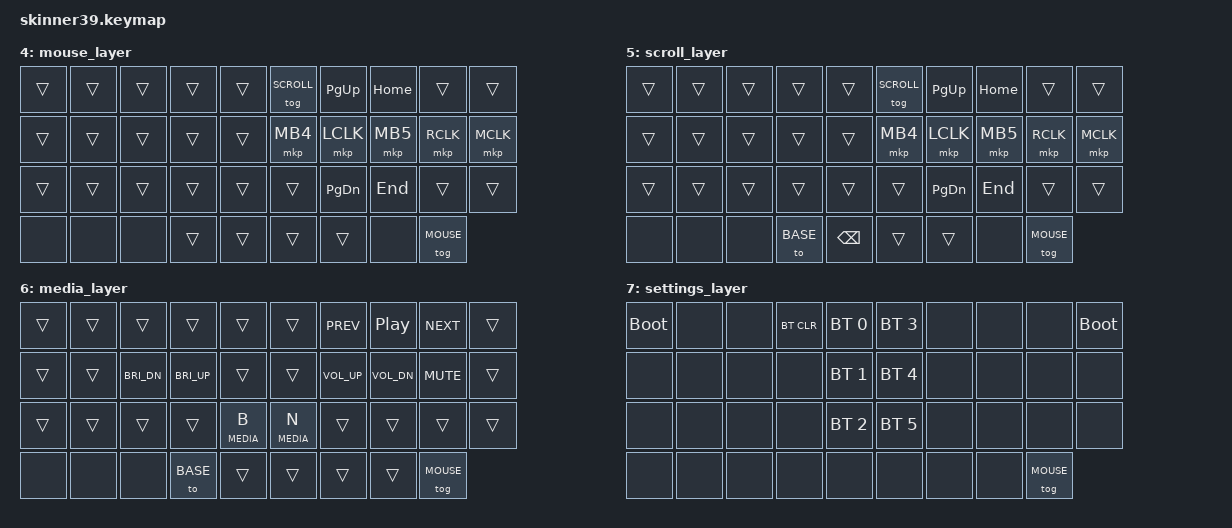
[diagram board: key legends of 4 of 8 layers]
#include <behaviors.dtsi>
#include <dt-bindings/zmk/bt.h>
#include <dt-bindings/zmk/keys.h>
#include <dt-bindings/zmk/mouse.h>
#include <dt-bindings/zmk/pointing.h>
#include <zephyr/dt-bindings/input/input-event-codes.h>

// Home row mods macro
#define HRML(k1,k2,k3,k4) &ht LSHFT k1  &ht LALT k2  &ht LCTRL k3  &ht LGUI k4
#define HRMR(k1,k2,k3,k4) &ht RGUI k1  &ht RCTRL k2  &ht RALT k3  &ht RSHFT k4
#define HYPERHT(k1) &ht LC(LS(LA(LGUI))) k1

// Layer definitions
#define BASE 0
#define NAV 1
#define NUM 2
#define SYMBOL 3
#define MOUSE 4
#define SCROLL 5
#define MEDIA 6
#define SETTINGS 7

&mmv {
    time-to-max-speed-ms = <500>;
};

/ {
    input_processors {
        // Maps Y movement to high-resolution vertical scroll
        zip_y_to_vscroll_mapper: zip_y_to_vscroll_mapper {
            compatible = "zmk,input-processor-code-mapper";
            #input-processor-cells = <0>;
            type = <INPUT_EV_REL>;
            map = <INPUT_REL_Y INPUT_REL_WHEEL>;  // Y only -> vertical scroll
        };
        
        // Inverts Y direction (scaler with -1 multiplier)
        zip_y_scaler_neg1_1: zip_y_scaler_neg1_1 {
            compatible = "zmk,input-processor-scaler";
            #input-processor-cells = <2>;  // Takes multiplier and divisor as params
            type = <INPUT_EV_REL>;
            codes = <INPUT_REL_Y>;
        };
        
        // Slows down scrolling (1/2 speed = 50%)
        zip_scroll_slow: zip_scroll_slow {
            compatible = "zmk,input-processor-scaler";
            #input-processor-cells = <2>;
            type = <INPUT_EV_REL>;
            codes = <INPUT_REL_Y>;
        };
        
    };

    macros {
        vol_up: vol_up {
            compatible = "zmk,behavior-macro";
            #binding-cells = <0>;
            bindings = <&kp C_VOL_UP>;
        };
        vol_down: vol_down {
            compatible = "zmk,behavior-macro";
            #binding-cells = <0>;
            bindings = <&kp C_VOL_DN>;
        };
    };

    behaviors {
        ht: hold_tap {
            compatible = "zmk,behavior-hold-tap";
            #binding-cells = <2>;
            flavor = "tap-preferred";
            tapping-term-ms = <220>;
            quick-tap-ms = <150>;
            bindings = <&kp>, <&kp>;
        };
    };

    combos {
        compatible = "zmk,combos";
        combo_caps_word {
            timeout-ms = <150>;
            key-positions = <20 29>;
            bindings = <&caps_word>;
        };
        combo_minus {
            timeout-ms = <150>;
            key-positions = <3 6>;
            bindings = <&kp MINUS>;
        };
        combo_under {
            timeout-ms = <150>;
            key-positions = <23 26>;
            bindings = <&kp UNDER>;
        };
    };

    keymap {
        compatible = "zmk,keymap";

        base_layer {
            bindings = <
        // Row 0: Main 5x3 grid (positions 0-4 left, 5-9 right)
        //╭──────────┬──────────┬──────────┬──────────┬──────────╮   ╭──────────┬──────────┬──────────┬──────────┬──────────╮
        //│  Q       │  W       │  E       │  R       │  T       │   │  Y       │  U       │  I       │  O       │  P       │
            &kp Q      &kp W      &kp E      &kp R      &kp T          &kp Y      &kp U      &kp I      &kp O      &kp P
        //├──────────┼──────────┼──────────┼──────────┼──────────┤   ├──────────┼──────────┼──────────┼──────────┼──────────┤
        // Row 1: Main 5x3 grid (positions 10-14 left, 15-19 right)
        //│  A       │  S       │  D       │  F       │  G       │   │  H       │  J       │  K       │  L       │    ' "   │
            HRML(A,        S,         D,         F)     &kp G          &kp H      HRMR(J,        K,         L,     APOSTROPHE)
        //├──────────┼──────────┼──────────┼──────────┼──────────┤   ├──────────┼──────────┼──────────┼──────────┼──────────┤
        // Row 2: Main 5x3 grid (positions 20-24 left, 25-29 right)
        //│  Z       │  X       │  C       │  V       │  B       │   │  N       │  M       │ , <      │ . >      │ / ?      │
            &kp Z      &kp X      &kp C      &kp V   &lt MEDIA B   &lt MEDIA N  &kp M   &kp COMMA  &kp DOT    &kp FSLH
        //╰──────────┴──────────┴──────────┴──────────┴──────────╯   ╰──────────┴──────────┴──────────┴──────────┴──────────╯

        // Row 3: Extra keys + Thumb keys (positions 30-38)
        // Layout: | Left Extra (3) | Left Thumbs (3) | Right Thumbs (2) | Right Extra (1) |
        // Matrix:   RC30 RC31 RC32   RC33 RC34 RC35   RC36 RC37          RC38
        //╭──────────┬──────────┬──────────┬──────────┬──────────┬──────────╮   ╭──────────┬──────────┬──────────╮
        //│ SCROLL   │  none    │  none    │  MOUSE   │ NUM/TAB  │HYPER/BSP │   │  SPACE   │  SPACE   │MOUSE TOG │
            &mo SCROLL &none      &none      &mo MOUSE  &lt NUM TAB    HYPERHT(BSPC)  &lt SYMBOL SPACE &lt NAV SPACE &tog MOUSE
        //╰──────────┴──────────┴──────────┴──────────┴──────────┴──────────╯   ╰──────────┴──────────┴──────────╯
            >;
        };

        nav_layer {
            bindings = <
        // Row 0
            &none &kp RG(W) &kp RG(LEFT_BRACKET) &kp RG(RIGHT_BRACKET) &kp RG(T)     &kp DEL &kp HOME &kp UP   &kp END  &kp PG_UP
        // Row 1
            HRML(DEL, LS(RG(I)), RC(LARW), RC(RARW))  &kp C_VOLUME_UP              &kp ENTER  &kp LARW   &kp DARW   &kp RARW   &kp PG_DN
        // Row 2
           &kp RG(Z)  &kp RG(X)  &kp RG(C) &kp RG(V) &kp C_VOLUME_DOWN             &none &kp RG(LA(LARW)) &kp RG(LA(DARW)) &kp RG(LA(UARW)) &kp RG(LA(RARW))
        // Row 3: Extra + Thumbs (new layout: MOUSE | NUM/TAB | HYPER/BSP)
            &none      &none      &none      &trans     &kp BSPC        &trans      &trans     &trans      &tog MOUSE
            >;
        };

        num_layer {
            bindings = <
        // Row 0
            &kp ESC    &trans      &trans    &kp TAB    &kp DEL        &kp FSLH    &kp N7    &kp N8     &kp N9     &kp KP_MINUS
        // Row 1
            HRML(EXCL,   AT,      HASH,       DLLR)     &kp PRCNT      &kp ENTER   &kp N4    &kp N5     &kp N6     &kp KP_PLUS
        // Row 2
           &kp RG(Z)  &kp RG(X)  &kp RG(C) &kp RG(V)    &none         &kp DOT      &kp N1    &kp N2     &kp N3     &kp ASTERISK
        // Row 3: Extra + Thumbs (new layout: MOUSE | NUM/TAB | HYPER/BSP)
            &none      &none      &none      &trans     &trans         &trans      &trans     &kp N0      &tog MOUSE
            >;
        };

        sym_layer {
            bindings = <
        // Row 0
            &kp EXCLAMATION &kp AT &kp HASH  &kp DOLLAR &kp PERCENT   &kp CARET  &kp LEFT_BRACKET &kp RIGHT_BRACKET &kp ASTERISK &kp EQUAL
        // Row 1
            HRML(GRAVE, TILDE, APOSTROPHE, DOUBLE_QUOTES) &kp PLUS                    &kp ENTER HRMR(LEFT_PARENTHESIS, RIGHT_PARENTHESIS, AMPERSAND, SEMICOLON)
        // Row 2
           &kp RG(Z)  &kp RG(X)  &kp RG(C) &kp RG(V)    &none        &none  &kp LEFT_BRACE &kp RIGHT_BRACE &kp BACKSLASH  &kp PIPE
        // Row 3: Extra + Thumbs (new layout: MOUSE | NUM/TAB | HYPER/BSP)
            &none      &none      &none      &trans   &mo SETTINGS     &trans      &trans      &none      &tog MOUSE
            >;
        };

        mouse_layer {
            bindings = <
        // Row 0
            &trans     &trans     &trans     &trans     &trans          &tog SCROLL &kp PG_UP  &kp HOME   &trans     &trans
        // Row 1
            &trans     &trans     &trans     &trans     &trans          &mkp MB4    &mkp LCLK  &mkp MB5   &mkp RCLK  &mkp MCLK
        // Row 2
            &trans     &trans     &trans     &trans     &trans          &trans      &kp PG_DN  &kp END    &trans     &trans
        // Row 3: Extra + Thumbs
            &none      &none      &none      &trans     &trans          &trans     &trans      &none      &tog MOUSE
            >;
        };

        scroll_layer {
            bindings = <
        // Row 0
            &trans     &trans     &trans     &trans     &trans          &tog SCROLL &kp PG_UP  &kp HOME   &trans     &trans
        // Row 1
            &trans     &trans     &trans     &trans     &trans          &mkp MB4    &mkp LCLK  &mkp MB5   &mkp RCLK  &mkp MCLK
        // Row 2
            &trans     &trans     &trans     &trans     &trans          &trans      &kp PG_DN  &kp END    &trans     &trans
        // Row 3: Extra + Thumbs - can return to BASE
        // Y-axis scrolling active on this layer (via input processor)
            &none      &none      &none      &to BASE   &kp BSPC        &trans     &trans      &none      &tog MOUSE
            >;
        };

        media_layer {
            bindings = <
        // Row 0: Media transport controls (moved right 1, up 1)
            &trans &trans &trans &trans &trans          &trans &kp C_PREV &kp C_PP &kp C_NEXT &trans
        // Row 1: Brightness (F/D positions) + Volume (moved up 1)
            &trans &trans &kp C_BRI_DN &kp C_BRI_UP &trans   &trans &kp C_VOL_UP &kp C_VOL_DN &kp C_MUTE &trans
        // Row 2: Just B/N layer triggers
            &trans &trans &trans &trans &lt MEDIA B     &lt MEDIA N &trans &trans &trans &trans
        // Row 3: Return to base
            &none &none &none &to BASE &trans           &trans &trans &trans &tog MOUSE
            >;
        };

        settings_layer {
            bindings = <
        // Row 0
            &bootloader &none    &none    &bt BT_CLR &bt BT_SEL 0     &bt BT_SEL 3 &none    &none    &none    &bootloader
        // Row 1
            &none     &none     &none     &none      &bt BT_SEL 1     &bt BT_SEL 4 &none    &none    &none    &none
        // Row 2
            &none     &none     &none     &none      &bt BT_SEL 2     &bt BT_SEL 5 &none    &none    &none    &none
        // Row 3: Extra + Thumbs (new layout: MOUSE | NUM/TAB | HYPER/BSP)
            &none      &none      &none      &none     &none            &none      &none      &none      &tog MOUSE
            >;
        };
    };
};
